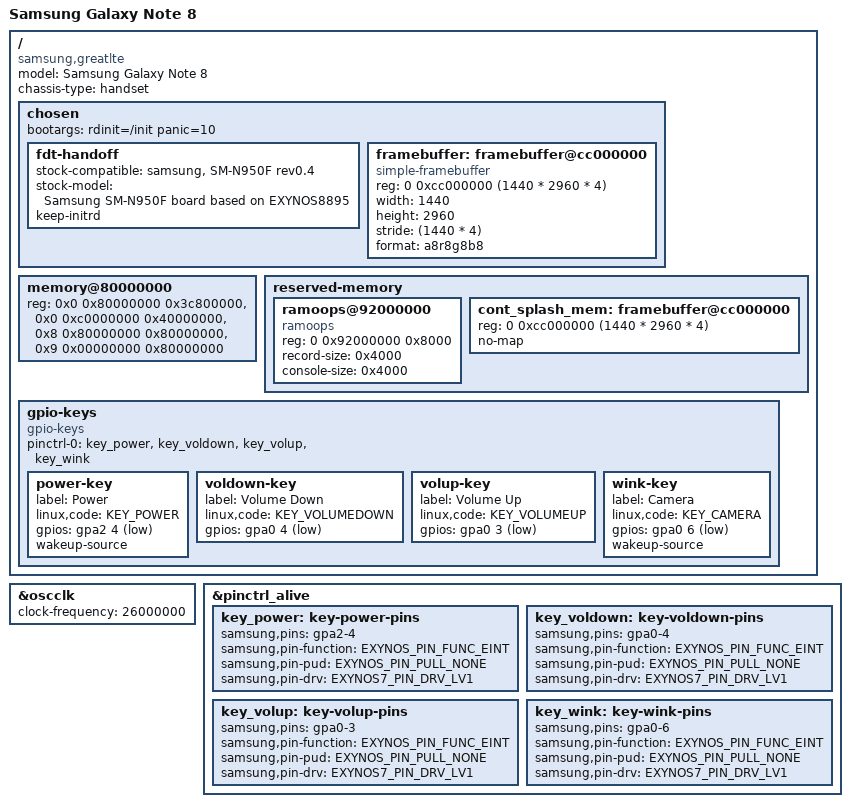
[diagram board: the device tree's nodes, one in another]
// SPDX-License-Identifier: GPL-2.0 OR BSD-3-Clause
/*
 * Samsung Galaxy Note 8 (greatlte/SM-N950N) device tree source
 *
 * Derived from the Galaxy S8 (dreamlte/SM-G950F) tree by Ivaylo Ivanov.
 *
 * This is a first-boot skeleton: the framebuffer, the keys and the ramoops
 * region, and the handoff description. Everything else of the device is a
 * step-3 item and is listed at the end of this file.
 *
 * The handoff identity, the memory map, the framebuffer address, the key
 * pins and the oscillator come from the stock tree of a unit that reports
 * SM-N950F (bootloader N950FXXUGDZEA) in /sys/firmware/fdt.
 */

/dts-v1/;
#include "exynos8895.dtsi"
#include <dt-bindings/gpio/gpio.h>
#include <dt-bindings/input/input.h>

/ {
	model = "Samsung Galaxy Note 8";
	compatible = "samsung,greatlte", "samsung,exynos8895";
	chassis-type = "handset";

	chosen {
		#address-cells = <2>;
		#size-cells = <1>;
		ranges;

		bootargs = "rdinit=/init panic=10";

		/*
		 * The bootloader's own tree, as /sys/firmware/fdt shows it. The
		 * compatible string has a space after its comma: that is how Samsung
		 * wrote it, and it must match exactly.
		 */
		fdt-handoff {
			stock-compatible = "samsung, SM-N950F rev0.4";
			stock-model = "Samsung SM-N950F board based on EXYNOS8895";
			keep-initrd;
		};

		/* s3cfb.bootloaderfb=0xcc000000 and a 1440x2960 DECON, as in the stock tree. */
		framebuffer: framebuffer@cc000000 {
			compatible = "simple-framebuffer";
			reg = <0 0xcc000000 (1440 * 2960 * 4)>;
			width = <1440>;
			height = <2960>;
			stride = <(1440 * 4)>;
			format = "a8r8g8b8";
		};
	};

	/*
	 * The Note 8 has 6 GB, the stock tree's four banks. The handoff
	 * replaces this map with the bootloader's usable memory.
	 */
	memory@80000000 {
		device_type = "memory";
		reg = <0x0 0x80000000 0x3c800000>,
		      <0x0 0xc0000000 0x40000000>,
		      <0x8 0x80000000 0x80000000>,
		      <0x9 0x00000000 0x80000000>;
	};

	reserved-memory {
		#address-cells = <2>;
		#size-cells = <1>;
		ranges;

		/*
		 * The S8's ramoops address. The stock tree does not reserve it, but the
		 * command line's ess_setup=0x91200000 has no size: if the phone resets
		 * without a log, suspect an overlap and move this.
		 */
		ramoops@92000000 {
			compatible = "ramoops";
			reg = <0 0x92000000 0x8000>;
			record-size = <0x4000>;
			console-size = <0x4000>;
		};

		cont_splash_mem: framebuffer@cc000000 {
			reg = <0 0xcc000000 (1440 * 2960 * 4)>;
			no-map;
		};
	};

	/* The pins of the stock tree's gpio_keys: gpa0-3, gpa0-4, gpa0-6, gpa2-4. */
	gpio-keys {
		compatible = "gpio-keys";

		pinctrl-0 = <&key_power &key_voldown &key_volup &key_wink>;
		pinctrl-names = "default";

		power-key {
			label = "Power";
			linux,code = <KEY_POWER>;
			gpios = <&gpa2 4 GPIO_ACTIVE_LOW>;
			wakeup-source;
		};

		voldown-key {
			label = "Volume Down";
			linux,code = <KEY_VOLUMEDOWN>;
			gpios = <&gpa0 4 GPIO_ACTIVE_LOW>;
		};

		volup-key {
			label = "Volume Up";
			linux,code = <KEY_VOLUMEUP>;
			gpios = <&gpa0 3 GPIO_ACTIVE_LOW>;
		};

		/* Bixby. Mapped as a camera button for now. */
		wink-key {
			label = "Camera";
			linux,code = <KEY_CAMERA>;
			gpios = <&gpa0 6 GPIO_ACTIVE_LOW>;
			wakeup-source;
		};
	};
};

&oscclk {
	clock-frequency = <26000000>;
};

&pinctrl_alive {
	key_power: key-power-pins {
		samsung,pins = "gpa2-4";
		samsung,pin-function = <EXYNOS_PIN_FUNC_EINT>;
		samsung,pin-pud = <EXYNOS_PIN_PULL_NONE>;
		samsung,pin-drv = <EXYNOS7_PIN_DRV_LV1>;
	};

	key_voldown: key-voldown-pins {
		samsung,pins = "gpa0-4";
		samsung,pin-function = <EXYNOS_PIN_FUNC_EINT>;
		samsung,pin-pud = <EXYNOS_PIN_PULL_NONE>;
		samsung,pin-drv = <EXYNOS7_PIN_DRV_LV1>;
	};

	key_volup: key-volup-pins {
		samsung,pins = "gpa0-3";
		samsung,pin-function = <EXYNOS_PIN_FUNC_EINT>;
		samsung,pin-pud = <EXYNOS_PIN_PULL_NONE>;
		samsung,pin-drv = <EXYNOS7_PIN_DRV_LV1>;
	};

	key_wink: key-wink-pins {
		samsung,pins = "gpa0-6";
		samsung,pin-function = <EXYNOS_PIN_FUNC_EINT>;
		samsung,pin-pud = <EXYNOS_PIN_PULL_NONE>;
		samsung,pin-drv = <EXYNOS7_PIN_DRV_LV1>;
	};
};

/*
 * Left out of the first boot, to add as step-3 items once the Note 8's own
 * stock tree and the reference kernel show what the board uses:
 *
 *  - touchscreen: the S8 has a Samsung S6SY761 on hsi2c_23 behind usi9; the
 *    Note 8's controller is not confirmed.
 *  - microSD: the S8's sd2 pins and card-detect GPIO (gpa1-5) are not
 *    confirmed, and the card's regulators need the PMIC.
 *  - the S2MPS PMICs, UFS, USB, display (DECON/DSI), charger and fuel gauge,
 *    Wi-Fi, Bluetooth, modem, sensors and the S Pen.
 */
